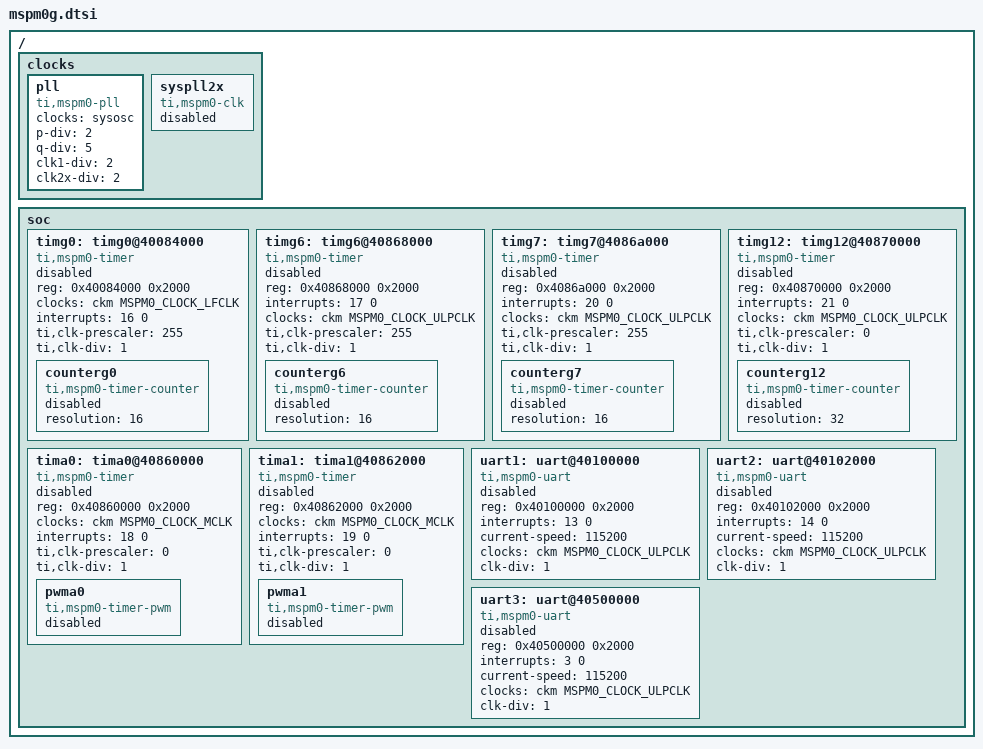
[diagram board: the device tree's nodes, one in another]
/*
 * Copyright (c) 2025 Texas Instruments
 * Copyright (c) 2025 Linumiz
 *
 * SPDX-License-Identifier: Apache-2.0
 */

#include <ti/mspm0/mspm0.dtsi>

/{
	clocks: clocks {
		pll: pll {
			compatible = "ti,mspm0-pll";
			clocks = <&sysosc>;
			p-div = <2>;
			q-div = <5>;
			clk1-div = <2>;
			clk2x-div = <2>;
			#clock-cells = <0>;
			status = "okay";
		};

		syspll2x: syspll2x {
			#clock-cells = <1>;
			compatible = "ti,mspm0-clk";
			status = "disabled";
		};
	};

	soc {
		timg0: timg0@40084000 {
			compatible = "ti,mspm0-timer";
			reg = <0x40084000 0x2000>;
			clocks = <&ckm MSPM0_CLOCK_LFCLK>;
			interrupts = <16 0>;
			ti,clk-prescaler = <255>;
			ti,clk-div = <1>;
			status = "disabled";

			counterg0: counterg0 {
				compatible = "ti,mspm0-timer-counter";
				resolution = <16>;
				status = "disabled";
			};
		};

		timg6: timg6@40868000 {
			compatible = "ti,mspm0-timer";
			reg = <0x40868000 0x2000>;
			interrupts = <17 0>;
			clocks = <&ckm MSPM0_CLOCK_ULPCLK>;
			ti,clk-prescaler = <255>;
			ti,clk-div = <1>;
			status = "disabled";

			counterg6: counterg6 {
				compatible = "ti,mspm0-timer-counter";
				resolution = <16>;
				status = "disabled";
			};
		};

		timg7: timg7@4086a000 {
			compatible = "ti,mspm0-timer";
			reg = <0x4086a000 0x2000>;
			interrupts = <20 0>;
			clocks = <&ckm MSPM0_CLOCK_ULPCLK>;
			ti,clk-prescaler = <255>;
			ti,clk-div = <1>;
			status = "disabled";

			counterg7: counterg7 {
				compatible = "ti,mspm0-timer-counter";
				resolution = <16>;
				status = "disabled";
			};
		};

		timg12: timg12@40870000 {
			compatible = "ti,mspm0-timer";
			reg = <0x40870000 0x2000>;
			interrupts = <21 0>;
			clocks = <&ckm MSPM0_CLOCK_ULPCLK>;
			ti,clk-prescaler = <0>; /* None */
			ti,clk-div = <1>;
			status = "disabled";

			counterg12: counterg12 {
				compatible = "ti,mspm0-timer-counter";
				resolution = <32>;
				status = "disabled";
			};
		};

		tima0: tima0@40860000 {
			compatible = "ti,mspm0-timer";
			reg = <0x40860000 0x2000>;
			clocks = <&ckm MSPM0_CLOCK_MCLK>;
			interrupts = <18 0>;
			ti,clk-prescaler = <0>;
			ti,clk-div = <1>;
			status = "disabled";

			pwma0: pwma0 {
				compatible = "ti,mspm0-timer-pwm";
				#pwm-cells = <3>;
				status = "disabled";
			};
		};

		tima1: tima1@40862000 {
			compatible = "ti,mspm0-timer";
			reg = <0x40862000 0x2000>;
			clocks = <&ckm MSPM0_CLOCK_MCLK>;
			interrupts = <19 0>;
			ti,clk-prescaler = <0>;
			ti,clk-div = <1>;
			status = "disabled";

			pwma1: pwma1 {
				compatible = "ti,mspm0-timer-pwm";
				#pwm-cells = <3>;
				status = "disabled";
			};
		};

		uart1: uart@40100000 {
			compatible = "ti,mspm0-uart";
			reg = <0x40100000 0x2000>;
			interrupts = <13 0>;
			current-speed = <115200>;
			clocks = <&ckm MSPM0_CLOCK_ULPCLK>;
			clk-div = <1>;
			status = "disabled";
		};

		uart2: uart@40102000 {
			compatible = "ti,mspm0-uart";
			reg = <0x40102000 0x2000>;
			interrupts = <14 0>;
			current-speed = <115200>;
			clocks = <&ckm MSPM0_CLOCK_ULPCLK>;
			clk-div = <1>;
			status = "disabled";
		};

		uart3: uart@40500000 {
			compatible = "ti,mspm0-uart";
			reg = <0x40500000 0x2000>;
			interrupts = <3 0>;
			current-speed = <115200>;
			clocks = <&ckm MSPM0_CLOCK_ULPCLK>;
			clk-div = <1>;
			status = "disabled";
		};
	};
};
